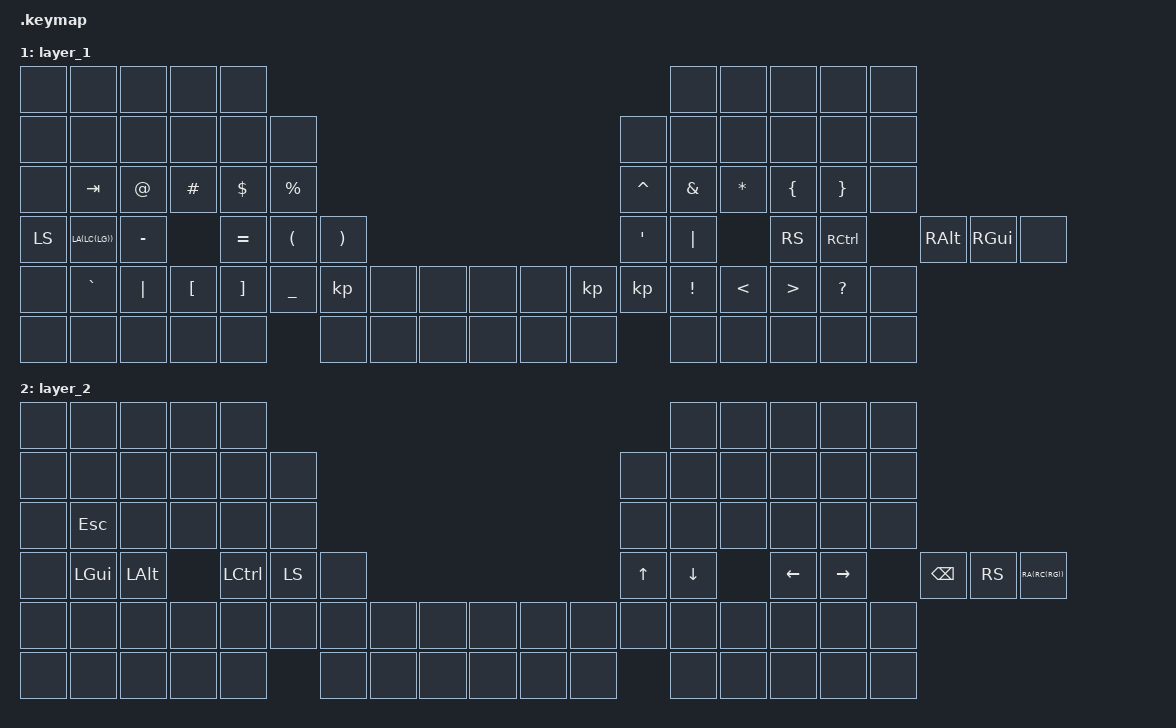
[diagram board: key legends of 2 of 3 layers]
/*
 * Copyright (c) 2020 The ZMK Contributors
 * Copyright (c) 2023 Innaworks Development Limited, trading as MoErgo
 *
 * SPDX-License-Identifier: MIT
 */
/* THIS FILE WAS GENERATED BY GLOVE80 LAYOUT EDITOR
 *
 * This file was generated automatically. You may or may not want to
 * edit it directly.
 */
/* Include all behaviour includes needed */

#include <behaviors.dtsi>
#include <dt-bindings/zmk/bt.h>
#include <dt-bindings/zmk/keys.h>
#include <dt-bindings/zmk/outputs.h>
#include <dt-bindings/zmk/rgb.h>

/* Automatically generated layer name #define */

#define LAYER_Base 0
#define LAYER_1 1
#define LAYER_2 2

/* To deal with the situation where there is no Lower layer, to keep &lower happy */

#ifndef LAYER_Lower

#define LAYER_Lower 0

#endif {
    /* Custom Device-tree */
    /* Glove80 system behavior & macros */

    /

    behaviors {
        // For the "layer" key, it'd nice to be able to use it as either a shift or a toggle.
        // Configure it as a tap dance, so the first tap (or hold) is a &mo and the second tap is a &to

        lower: lower {
            compatible = "zmk,behavior-tap-dance";
            label = "LAYER_TAP_DANCE";
            #binding-cells = <0>;
            tapping-term-ms = <200>;
            bindings = <&mo LAYER_Lower>, <&to LAYER_Lower>;
        };
    };
};

/ {
    macros {
        rgb_ug_status_macro: rgb_ug_status_macro {
            label = "RGB_UG_STATUS";
            compatible = "zmk,behavior-macro";
            #binding-cells = <0>;
            bindings = <&rgb_ug RGB_STATUS>;
        };
    };
};

/ {
    #ifdef BT_DISC_CMD

    behaviors {
        bt_0: bt_0 {
            compatible = "zmk,behavior-tap-dance";
            label = "BT_0";
            #binding-cells = <0>;
            tapping-term-ms = <200>;
            bindings = <&bt_select_0>, <&bt BT_DISC 0>;
        };

        bt_1: bt_1 {
            compatible = "zmk,behavior-tap-dance";
            label = "BT_1";
            #binding-cells = <0>;
            tapping-term-ms = <200>;
            bindings = <&bt_select_1>, <&bt BT_DISC 1>;
        };

        bt_2: bt_2 {
            compatible = "zmk,behavior-tap-dance";
            label = "BT_2";
            #binding-cells = <0>;
            tapping-term-ms = <200>;
            bindings = <&bt_select_2>, <&bt BT_DISC 2>;
        };

        bt_3: bt_3 {
            compatible = "zmk,behavior-tap-dance";
            label = "BT_3";
            #binding-cells = <0>;
            tapping-term-ms = <200>;
            bindings = <&bt_select_3>, <&bt BT_DISC 3>;
        };
    };

    macros {
        bt_select_0: bt_select_0 {
            label = "BT_SELECT_0";
            compatible = "zmk,behavior-macro";
            #binding-cells = <0>;
            bindings = <&out OUT_BLE &bt BT_SEL 0>;
        };

        bt_select_1: bt_select_1 {
            label = "BT_SELECT_1";
            compatible = "zmk,behavior-macro";
            #binding-cells = <0>;
            bindings = <&out OUT_BLE &bt BT_SEL 1>;
        };

        bt_select_2: bt_select_2 {
            label = "BT_SELECT_2";
            compatible = "zmk,behavior-macro";
            #binding-cells = <0>;
            bindings = <&out OUT_BLE &bt BT_SEL 2>;
        };

        bt_select_3: bt_select_3 {
            label = "BT_SELECT_3";
            compatible = "zmk,behavior-macro";
            #binding-cells = <0>;
            bindings = <&out OUT_BLE &bt BT_SEL 3>;
        };
    };

    #else

    macros {
        bt_0: bt_0 {
            label = "BT_0";
            compatible = "zmk,behavior-macro";
            #binding-cells = <0>;
            bindings = <&out OUT_BLE &bt BT_SEL 0>;
        };

        bt_1: bt_1 {
            label = "BT_1";
            compatible = "zmk,behavior-macro";
            #binding-cells = <0>;
            bindings = <&out OUT_BLE &bt BT_SEL 1>;
        };

        bt_2: bt_2 {
            label = "BT_2";
            compatible = "zmk,behavior-macro";
            #binding-cells = <0>;
            bindings = <&out OUT_BLE &bt BT_SEL 2>;
        };

        bt_3: bt_3 {
            label = "BT_3";
            compatible = "zmk,behavior-macro";
            #binding-cells = <0>;
            bindings = <&out OUT_BLE &bt BT_SEL 3>;
        };
    };

    #endif
};

/ {
    behaviors {
        magic: magic {
            compatible = "zmk,behavior-hold-tap";
            label = "MAGIC_HOLD_TAP";
            #binding-cells = <2>;
            flavor = "tap-preferred";
            tapping-term-ms = <200>;
            bindings = <&mo>, <&rgb_ug_status_macro>;
        };
    };
};

/* #define for key positions */

#define POS_LH_T1 52
#define POS_LH_T2 53
#define POS_LH_T3 54
#define POS_LH_T4 69
#define POS_LH_T5 70
#define POS_LH_T6 71
#define POS_LH_C1R2 15
#define POS_LH_C1R3 27
#define POS_LH_C1R4 39
#define POS_LH_C1R5 51
#define POS_LH_C2R1 4
#define POS_LH_C2R2 14
#define POS_LH_C2R3 26
#define POS_LH_C2R4 38
#define POS_LH_C2R5 50
#define POS_LH_C2R6 68
#define POS_LH_C3R1 3
#define POS_LH_C3R2 13
#define POS_LH_C3R3 25
#define POS_LH_C3R4 37
#define POS_LH_C3R5 49
#define POS_LH_C3R6 67
#define POS_LH_C4R1 2
#define POS_LH_C4R2 12
#define POS_LH_C4R3 24
#define POS_LH_C4R4 36
#define POS_LH_C4R5 48
#define POS_LH_C4R6 66
#define POS_LH_C5R1 1
#define POS_LH_C5R2 11
#define POS_LH_C5R3 23
#define POS_LH_C5R4 35
#define POS_LH_C5R5 47
#define POS_LH_C5R6 65
#define POS_LH_C6R1 0
#define POS_LH_C6R2 10
#define POS_LH_C6R3 22
#define POS_LH_C6R4 34
#define POS_LH_C6R5 46
#define POS_LH_C6R6 64
#define POS_RH_T1 57
#define POS_RH_T2 56
#define POS_RH_T3 55
#define POS_RH_T4 74
#define POS_RH_T5 73
#define POS_RH_T6 72
#define POS_RH_C1R2 16
#define POS_RH_C1R3 28
#define POS_RH_C1R4 40
#define POS_RH_C1R5 58
#define POS_RH_C2R1 5
#define POS_RH_C2R2 17
#define POS_RH_C2R3 29
#define POS_RH_C2R4 41
#define POS_RH_C2R5 59
#define POS_RH_C2R6 75
#define POS_RH_C3R1 6
#define POS_RH_C3R2 18
#define POS_RH_C3R3 30
#define POS_RH_C3R4 42
#define POS_RH_C3R5 60
#define POS_RH_C3R6 76
#define POS_RH_C4R1 7
#define POS_RH_C4R2 19
#define POS_RH_C4R3 31
#define POS_RH_C4R4 43
#define POS_RH_C4R5 61
#define POS_RH_C4R6 77
#define POS_RH_C5R1 8
#define POS_RH_C5R2 20
#define POS_RH_C5R3 32
#define POS_RH_C5R4 44
#define POS_RH_C5R5 62
#define POS_RH_C5R6 78
#define POS_RH_C6R1 9
#define POS_RH_C6R2 21
#define POS_RH_C6R3 33
#define POS_RH_C6R4 45
#define POS_RH_C6R5 63
#define POS_RH_C6R6 79

/* Custom Defined Behaviors */

/ {
};

/* Automatically generated macro definitions */

/ {
    macros {
    };
};

/* Automatically generated keymap */

/ {
    keymap {
        compatible = "zmk,keymap";

        layer_Base {
            bindings = <
&kp F1                    &kp F2    &kp F3   &kp F4    &kp F5                                                                                   &kp F6  &kp F7     &kp F8    &kp F9    &kp F10
&kp EQUAL                 &kp N1    &kp N2   &kp N3    &kp N4     &kp N5                                                                &kp N6  &kp N7  &kp N8     &kp N9    &kp N0    &kp MINUS
&kp TAB                   &kp Q     &kp W    &kp E     &kp R      &kp T                                                                 &kp Y   &kp U   &kp I      &kp O     &kp P     &kp BSLH
&mt LC(ESC)                   &kp A     &kp S    &kp D     &kp F      &kp G                                                                 &kp H   &kp J   &kp K      &kp L     &kp SEMI  &mt SQT RCTRL
&kp GRAVE                 &kp Z     &kp X    &kp C     &kp V      &kp B   &kp SPACE  &mo 2    &none       &kp LGUI  &mo 1    &kp RSHFT  &kp N   &kp M   &kp COMMA  &kp DOT   &kp FSLH  &kp PG_UP
&kp LS(LA(LC(LG(LALT))))  &kp HOME  &kp END  &kp LEFT  &kp RIGHT          &kp LGUI   &kp DEL  &kp LALT    &kp RALT  &kp RET  &kp RET            &kp UP  &kp DOWN   &kp LBKT  &kp RBKT  &kp PG_DN
            >;
        };

        layer_1 {
            bindings = <
&none                       &none        &none        &none                   &none                                                                                       &none       &none            &none               &none        &none
&none                       &none        &none        &none                   &none                    &none                                                     &none        &none       &none            &none               &none    &none
&none                       &kp TAB        &kp AT     &kp HASH              &kp DOLLAR             &kp PERCENT                                             &kp CARET  &kp AMPS  &kp ASTRK      &kp LBRC          &kp RBRC   &none
&kp LS(LA(LC(LG)))  &kp MINUS  &kp EQUAL  &kp LEFT_PARENTHESIS  &kp RIGHT_PARENTHESIS  &kp  SQT                                                   &kp PIPE   &kp RS    &kp RCTRL      &kp RALT          &kp RGUI   &none
&none                       &kp GRAVE  &kp PIPE   &kp LBKT              &kp RBKT               &kp UNDERSCORE  &kp  &none  &none    &none  &none  &kp  &kp        &kp EXCL  &kp LESS_THAN  &kp GREATER_THAN  &kp QMARK  &none
&none                       &none        &none        &none                   &none                                    &none  &none    &none      &none    &none    &none             &none       &none            &none               &none        &none
            >;
        };

        layer_2 {
            bindings = <
&none  &none  &none  &none  &none                                                            &none  &none  &none  &none  &none
&none  &none  &none  &none  &none  &none                                              &none  &none  &none  &none  &none  &none
&none  &kp ESC  &none  &none  &none  &none                                              &none  &none  &none  &none  &none  &none
&none  &kp LGUI  &kp LALT  &kp LCTRL  &LS  &none                                      &kp UP  &kp DOWN  &kp LEFT  &kp RIGHT  &kp BSPC  &kp RS(RA(RC(RG)))
&none  &none  &none  &none  &none  &none  &none  &none  &none    &none  &none  &none  &none  &none  &none  &none  &none  &none
&none  &none  &none  &none  &none         &none  &none  &none    &none  &none  &none         &none  &none  &none  &none  &none
            >;
        };
    };
};
